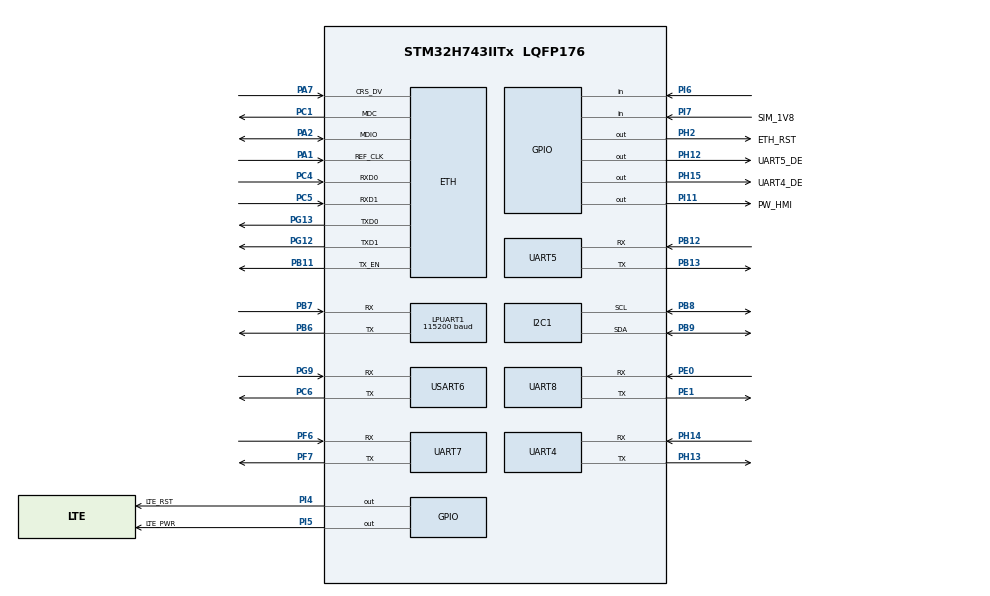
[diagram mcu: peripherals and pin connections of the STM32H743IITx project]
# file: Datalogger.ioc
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CORTEX_M7.AccessPermission_S-Cortex_Memory_Protection_Unit_Region1_Settings_S=MPU_REGION_FULL_ACCESS
CORTEX_M7.AccessPermission_S-Cortex_Memory_Protection_Unit_Region2_Settings_S=MPU_REGION_FULL_ACCESS
CORTEX_M7.AccessPermission_Spec=MPU_REGION_NO_ACCESS
CORTEX_M7.BaseAddress_S-Cortex_Memory_Protection_Unit_Region1_Settings_S=0x30020000
CORTEX_M7.BaseAddress_S-Cortex_Memory_Protection_Unit_Region2_Settings_S=30040000
CORTEX_M7.BaseAddress_Spec=0x0
CORTEX_M7.CPU_DCache=Enabled
CORTEX_M7.CPU_ICache=Enabled
CORTEX_M7.DisableExec_S-Cortex_Memory_Protection_Unit_Region1_Settings_S=MPU_INSTRUCTION_ACCESS_DISABLE
CORTEX_M7.DisableExec_S-Cortex_Memory_Protection_Unit_Region2_Settings_S=MPU_INSTRUCTION_ACCESS_DISABLE
CORTEX_M7.DisableExec_Spec=MPU_INSTRUCTION_ACCESS_DISABLE
CORTEX_M7.Enable_S-Cortex_Memory_Protection_Unit_Region1_Settings_S=MPU_REGION_ENABLE
CORTEX_M7.Enable_S-Cortex_Memory_Protection_Unit_Region2_Settings_S=MPU_REGION_ENABLE
CORTEX_M7.Enable_Spec=__NULL
CORTEX_M7.IsBufferable_S-Cortex_Memory_Protection_Unit_Region2_Settings_S=MPU_ACCESS_BUFFERABLE
CORTEX_M7.IsBufferable_Spec=MPU_ACCESS_NOT_BUFFERABLE
CORTEX_M7.IsCacheable_S-Cortex_Memory_Protection_Unit_Region1_Settings_S=MPU_ACCESS_NOT_CACHEABLE
CORTEX_M7.IsCacheable_Spec=MPU_ACCESS_NOT_CACHEABLE
CORTEX_M7.IsShareable_S-Cortex_Memory_Protection_Unit_Region2_Settings_S=MPU_ACCESS_SHAREABLE
CORTEX_M7.IsShareable_Spec=MPU_ACCESS_SHAREABLE
CORTEX_M7.MPU_Control=MPU_PRIVILEGED_DEFAULT
CORTEX_M7.Size_S-Cortex_Memory_Protection_Unit_Region1_Settings_S=MPU_REGION_SIZE_128KB
CORTEX_M7.Size_S-Cortex_Memory_Protection_Unit_Region2_Settings_S=MPU_REGION_SIZE_512B
CORTEX_M7.Size_Spec=MPU_REGION_SIZE_4GB
CORTEX_M7.SubRegionDisable_Spec=0x87
CORTEX_M7.TypeExtField_S-Cortex_Memory_Protection_Unit_Region1_Settings_S=MPU_TEX_LEVEL1
CORTEX_M7.TypeExtField_Spec=MPU_TEX_LEVEL0
CORTEX_M7.default_mode_Activation=1
ETH.MediaInterface=HAL_ETH_RMII_MODE
ETH.RxBufferAddress=0x30040260
ETH.RxDescAddress=0x30040000
ETH.TxDescAddress=0x30040200
FREERTOS.Tasks01=defaultTask,24,256,StartDefaultTask,Default,NULL,Dynamic,NULL,NULL
FREERTOS.configCHECK_FOR_STACK_OVERFLOW=2
FREERTOS.configMINIMAL_STACK_SIZE=256
FREERTOS.configRECORD_STACK_HIGH_ADDRESS=1
FREERTOS.configTOTAL_HEAP_SIZE=40000
FREERTOS.configUSE_NEWLIB_REENTRANT=1
FREERTOS.configUSE_STATS_FORMATTING_FUNCTIONS=1
I2C1.Timing=0x2050517A
LPUART1.BaudRate=115200
LWIP.BSP.number=1
LWIP.GATEWAY_ADDRESS=192.168.001.001
LWIP.IP_ADDRESS=192.168.110.056
LWIP.LWIP_DHCP=1
LWIP.LWIP_DNS=1
LWIP.LWIP_IPV6=0
LWIP.LWIP_RAM_HEAP_POINTER=0x30020000
LWIP.LWIP_SNTP=1
LWIP.LWIP_STATS=1
LWIP.MEM_SIZE=131048
LWIP.NETMASK_ADDRESS=255.255.255.000
LWIP.PPPOE_SUPPORT=1
LWIP.PPPOL2TP_AUTH_SUPPORT=0
LWIP.PPPOL2TP_SUPPORT=0
LWIP.PPP_NOTIFY_PHASE=1
LWIP.PPP_SUPPORT=1
LWIP.Version=v2.1.2_Cube
LWIP0.BSP.STBoard=false
LWIP0.BSP.api=BSP_COMPONENT_DRIVER
LWIP0.BSP.component=LAN8742
LWIP0.BSP.instance=LAN8742
LWIP0.BSP.name=Driver_PHY
LWIP0.BSP.semaphore=S_LAN8742
LWIP0.BSP.solution=LAN8742
Mcu.Family=STM32H7
Mcu.Name=STM32H743IITx
Mcu.Package=LQFP176
NVIC.ETH_IRQn=true\:5\:0\:false\:false\:true\:true\:true\:true\:true
NVIC.I2C1_EV_IRQn=true\:5\:0\:false\:false\:true\:true\:true\:true\:true
NVIC.LPUART1_IRQn=true\:5\:0\:false\:false\:true\:true\:true\:true\:true
NVIC.PriorityGroup=NVIC_PRIORITYGROUP_4
NVIC.TIM1_UP_IRQn=true\:5\:0\:false\:false\:true\:true\:true\:true\:true
NVIC.TIM2_IRQn=true\:5\:0\:false\:false\:true\:true\:true\:true\:true
NVIC.TIM3_IRQn=true\:5\:0\:false\:false\:true\:true\:true\:true\:true
NVIC.TIM4_IRQn=true\:5\:0\:false\:false\:true\:true\:true\:true\:true
NVIC.TIM5_IRQn=true\:5\:0\:false\:false\:true\:true\:true\:true\:true
NVIC.TIM6_DAC_IRQn=true\:15\:0\:false\:false\:true\:false\:false\:true\:true
NVIC.TimeBase=TIM6_DAC_IRQn
NVIC.TimeBaseIP=TIM6
NVIC.UART4_IRQn=true\:5\:0\:false\:false\:true\:true\:true\:true\:true
NVIC.UART5_IRQn=true\:5\:0\:false\:false\:true\:true\:true\:true\:true
NVIC.UART7_IRQn=true\:5\:0\:false\:false\:true\:true\:true\:true\:true
NVIC.UART8_IRQn=true\:5\:0\:false\:false\:true\:true\:true\:true\:true
NVIC.USART6_IRQn=true\:5\:0\:false\:false\:true\:true\:true\:true\:true
PA1.Mode=RMII
PA1.Signal=ETH_REF_CLK
PA13\ (JTMS/SWDIO).Mode=Serial_Wire
PA13\ (JTMS/SWDIO).Signal=DEBUG_JTMS-SWDIO
PA14\ (JTCK/SWCLK).Mode=Serial_Wire
PA14\ (JTCK/SWCLK).Signal=DEBUG_JTCK-SWCLK
PA2.Mode=RMII
PA2.Signal=ETH_MDIO
PA7.Mode=RMII
PA7.Signal=ETH_CRS_DV
PB11.Mode=RMII
PB11.Signal=ETH_TX_EN
PB12.Mode=Asynchronous
PB12.Signal=UART5_RX
PB13.Mode=Asynchronous
PB13.Signal=UART5_TX
PB6.Mode=Asynchronous
PB6.Signal=LPUART1_TX
PB7.Mode=Asynchronous
PB7.Signal=LPUART1_RX
PB8.Mode=I2C
PB8.Signal=I2C1_SCL
PB9.Mode=I2C
PB9.Signal=I2C1_SDA
PC1.Mode=RMII
PC1.Signal=ETH_MDC
PC4.Mode=RMII
PC4.Signal=ETH_RXD0
PC5.Mode=RMII
PC5.Signal=ETH_RXD1
PC6.Mode=Asynchronous
PC6.Signal=USART6_TX
PE0.Mode=Asynchronous
PE0.Signal=UART8_RX
PE1.Mode=Asynchronous
PE1.Signal=UART8_TX
PF6.Mode=Asynchronous
PF6.Signal=UART7_RX
PF7.Mode=Asynchronous
PF7.Signal=UART7_TX
PG12.Mode=RMII
PG12.Signal=ETH_TXD1
PG13.Mode=RMII
PG13.Signal=ETH_TXD0
PG9.Mode=Asynchronous
PG9.Signal=USART6_RX
PH0-OSC_IN\ (PH0).Mode=HSE-External-Oscillator
PH0-OSC_IN\ (PH0).Signal=RCC_OSC_IN
PH1-OSC_OUT\ (PH1).Mode=HSE-External-Oscillator
PH1-OSC_OUT\ (PH1).Signal=RCC_OSC_OUT
PH12.GPIO_Label=UART5_DE
PH12.Signal=GPIO_Output
PH13.Mode=Asynchronous
PH13.Signal=UART4_TX
PH14.Mode=Asynchronous
PH14.Signal=UART4_RX
PH15.GPIO_Label=UART4_DE
PH15.Signal=GPIO_Output
PH2.GPIO_Label=ETH_RST
PH2.Signal=GPIO_Output
PI11.GPIO_Label=PW_HMI
PI11.Signal=GPIO_Output
PI4.GPIO_Label=LTE_RST
PI4.Signal=GPIO_Output
PI5.GPIO_Label=LTE_PWR
PI5.Signal=GPIO_Output
PI6.Signal=GPIO_Input
PI7.GPIO_Label=SIM_1V8
PI7.Signal=GPIO_Input
ProjectManager.HeapSize=0x2000
ProjectManager.StackSize=0x4000
ProjectManager.TargetToolchain=STM32CubeIDE
RCC.ADCFreq_Value=16125000
RCC.APB1Freq_Value=62500000
RCC.APB2Freq_Value=62500000
RCC.APB3Freq_Value=62500000
RCC.APB4Freq_Value=62500000
RCC.CortexFreq_Value=250000000
RCC.D1PPRE=RCC_APB3_DIV2
RCC.D2PPRE1=RCC_APB1_DIV2
RCC.D2PPRE2=RCC_APB2_DIV2
RCC.D3PPRE=RCC_APB4_DIV2
RCC.DIVM1=1
RCC.DIVN1=62
RCC.HCLKFreq_Value=125000000
RCC.HPRE=RCC_HCLK_DIV2
RCC.HSE_VALUE=8000000
RCC.PLL2FRACN=0
RCC.PLL3FRACN=0
RCC.PLLFRACN=4096
RCC.PLLSourceVirtual=RCC_PLLSOURCE_HSE
RCC.SYSCLKFreq_VALUE=250000000
RCC.SYSCLKSource=RCC_SYSCLKSOURCE_PLLCLK
RCC.USBFreq_Value=250000000
TIM1.Period=999
TIM1.Prescaler=124
TIM2.Period=9999
TIM2.Prescaler=124
USART6.SwapParam=ADVFEATURE_SWAP_DISABLE
USART6.VirtualMode-Asynchronous=VM_ASYNC
VP_FREERTOS_VS_CMSIS_V2.Mode=CMSIS_V2
VP_LWIP_VS_Enabled.Mode=Enabled
VP_MEMORYMAP_VS_MEMORYMAP.Mode=CurAppReg
VP_SYS_VS_tim6.Mode=TIM6
VP_TIM1_VS_ClockSourceINT.Mode=Internal
VP_TIM2_VS_ClockSourceINT.Mode=Internal
VP_TIM3_VS_ClockSourceINT.Mode=Internal
VP_TIM4_VS_ClockSourceINT.Mode=Internal
VP_TIM5_VS_ClockSourceINT.Mode=Internal
board=custom

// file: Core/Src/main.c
/* USER CODE BEGIN Header */
/**
  ******************************************************************************
  * @file           : main.c
  * @brief          : Main program body
  ******************************************************************************
  * @attention
  *
  * Copyright (c) 2025 STMicroelectronics.
  * All rights reserved.
  *
  * This software is licensed under terms that can be found in the LICENSE file
  * in the root directory of this software component.
  * If no LICENSE file comes with this software, it is provided AS-IS.
  *
  ******************************************************************************
  */
/* USER CODE END Header */
#include "main.h"
#include "cmsis_os.h"
#include "i2c.h"
#include "usart.h"
#include "lwip.h"
#include "tim.h"
#include "gpio.h"

/* USER CODE BEGIN Includes */
#include "board.h"
/* USER CODE END Includes */

void SystemClock_Config(void);
static void MPU_Config(void);
void MX_FREERTOS_Init(void);

int main(void)
{

  /* USER CODE BEGIN 1 */
  int wait = 10000000;
  while (wait-- >0);
  /* USER CODE END 1 */

  /* MPU Configuration--------------------------------------------------------*/
  MPU_Config();

  /* Enable the CPU Cache */

  /* Enable I-Cache---------------------------------------------------------*/
  SCB_EnableICache();

  /* Enable D-Cache---------------------------------------------------------*/
  SCB_EnableDCache();

  /* MCU Configuration--------------------------------------------------------*/

  /* Reset of all peripherals, Initializes the Flash interface and the Systick. */
  HAL_Init();

  /* Configure the system clock */
  SystemClock_Config();

  /* Initialize all configured peripherals */
  MX_GPIO_Init();
  bsp_power_off_hmi();
  MX_I2C1_Init();
  MX_LPUART1_UART_Init();
  MX_UART4_Init();
  MX_UART5_Init();
  MX_UART7_Init();
  MX_UART8_Init();
  MX_TIM1_Init();
  MX_TIM2_Init();
  MX_TIM3_Init();
  MX_TIM4_Init();
  MX_TIM5_Init();
  MX_USART6_UART_Init();
  /* USER CODE BEGIN 2 */
  HAL_Delay(1000);
  /* USER CODE END 2 */

  /* Init scheduler */
  osKernelInitialize();  /* Call init function for freertos objects (in cmsis_os2.c) */
  MX_FREERTOS_Init();

  /* Start scheduler */
  osKernelStart();

  /* We should never get here as control is now taken by the scheduler */

  /* Infinite loop */
  while (1)
  {

  }
}

void SystemClock_Config(void)
{
  RCC_OscInitTypeDef RCC_OscInitStruct = {0};
  RCC_ClkInitTypeDef RCC_ClkInitStruct = {0};

  /** Supply configuration update enable
  */
  HAL_PWREx_ConfigSupply(PWR_LDO_SUPPLY);

  /** Configure the main internal regulator output voltage
  */
  __HAL_PWR_VOLTAGESCALING_CONFIG(PWR_REGULATOR_VOLTAGE_SCALE2);

  while(!__HAL_PWR_GET_FLAG(PWR_FLAG_VOSRDY)) {}

  /** Initializes the RCC Oscillators according to the specified parameters
  * in the RCC_OscInitTypeDef structure.
  */
  RCC_OscInitStruct.OscillatorType = RCC_OSCILLATORTYPE_HSE;
  RCC_OscInitStruct.HSEState = RCC_HSE_ON;
  RCC_OscInitStruct.PLL.PLLState = RCC_PLL_ON;
  RCC_OscInitStruct.PLL.PLLSource = RCC_PLLSOURCE_HSE;
  RCC_OscInitStruct.PLL.PLLM = 1;
  RCC_OscInitStruct.PLL.PLLN = 62;
  RCC_OscInitStruct.PLL.PLLP = 2;
  RCC_OscInitStruct.PLL.PLLQ = 2;
  RCC_OscInitStruct.PLL.PLLR = 2;
  RCC_OscInitStruct.PLL.PLLRGE = RCC_PLL1VCIRANGE_3;
  RCC_OscInitStruct.PLL.PLLVCOSEL = RCC_PLL1VCOWIDE;
  RCC_OscInitStruct.PLL.PLLFRACN = 4096;
  if (HAL_RCC_OscConfig(&RCC_OscInitStruct) != HAL_OK)
  {
    Error_Handler();
  }

  /** Initializes the CPU, AHB and APB buses clocks
  */
  RCC_ClkInitStruct.ClockType = RCC_CLOCKTYPE_HCLK|RCC_CLOCKTYPE_SYSCLK
                              |RCC_CLOCKTYPE_PCLK1|RCC_CLOCKTYPE_PCLK2
                              |RCC_CLOCKTYPE_D3PCLK1|RCC_CLOCKTYPE_D1PCLK1;
  RCC_ClkInitStruct.SYSCLKSource = RCC_SYSCLKSOURCE_PLLCLK;
  RCC_ClkInitStruct.SYSCLKDivider = RCC_SYSCLK_DIV1;
  RCC_ClkInitStruct.AHBCLKDivider = RCC_HCLK_DIV2;
  RCC_ClkInitStruct.APB3CLKDivider = RCC_APB3_DIV2;
  RCC_ClkInitStruct.APB1CLKDivider = RCC_APB1_DIV2;
  RCC_ClkInitStruct.APB2CLKDivider = RCC_APB2_DIV2;
  RCC_ClkInitStruct.APB4CLKDivider = RCC_APB4_DIV2;

  if (HAL_RCC_ClockConfig(&RCC_ClkInitStruct, FLASH_LATENCY_2) != HAL_OK)
  {
    Error_Handler();
  }
}

 /* MPU Configuration */

void MPU_Config(void)
{
  MPU_Region_InitTypeDef MPU_InitStruct = {0};

  /* Disables the MPU */
  HAL_MPU_Disable();

  /** Initializes and configures the Region and the memory to be protected
  */
  MPU_InitStruct.Enable = MPU_REGION_ENABLE;
  MPU_InitStruct.BaseAddress = 0x30020000;
  MPU_InitStruct.Size = MPU_REGION_SIZE_128KB;
  MPU_InitStruct.SubRegionDisable = 0x0;
  MPU_InitStruct.TypeExtField = MPU_TEX_LEVEL1;
  MPU_InitStruct.AccessPermission = MPU_REGION_FULL_ACCESS;
  MPU_InitStruct.DisableExec = MPU_INSTRUCTION_ACCESS_DISABLE;
  MPU_InitStruct.IsShareable = MPU_ACCESS_NOT_SHAREABLE;
  MPU_InitStruct.IsCacheable = MPU_ACCESS_NOT_CACHEABLE;
  MPU_InitStruct.IsBufferable = MPU_ACCESS_NOT_BUFFERABLE;

  HAL_MPU_ConfigRegion(&MPU_InitStruct);

  /** Initializes and configures the Region and the memory to be protected
  */
  MPU_InitStruct.BaseAddress = 30040000;
  MPU_InitStruct.Size = MPU_REGION_SIZE_512B;
  MPU_InitStruct.TypeExtField = MPU_TEX_LEVEL0;
  MPU_InitStruct.IsShareable = MPU_ACCESS_SHAREABLE;
  MPU_InitStruct.IsBufferable = MPU_ACCESS_BUFFERABLE;

  HAL_MPU_ConfigRegion(&MPU_InitStruct);
  /* Enables the MPU */
  HAL_MPU_Enable(MPU_PRIVILEGED_DEFAULT);

}

void HAL_TIM_PeriodElapsedCallback(TIM_HandleTypeDef *htim)
{
  if (htim->Instance == TIM6)
  {
    HAL_IncTick();
  }
  /* USER CODE BEGIN Callback 1 */
  BSP_TIM_PeriodElapsedCallback(htim);
  /* USER CODE END Callback 1 */
}

void Error_Handler(void)
{
  __disable_irq();
  while (1)
  {
  }
}

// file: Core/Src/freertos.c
/* USER CODE BEGIN Header */
/**
  ******************************************************************************
  * File Name          : freertos.c
  * Description        : Code for freertos applications
  ******************************************************************************
  * @attention
  *
  * Copyright (c) 2025 STMicroelectronics.
  * All rights reserved.
  *
  * This software is licensed under terms that can be found in the LICENSE file
  * in the root directory of this software component.
  * If no LICENSE file comes with this software, it is provided AS-IS.
  *
  ******************************************************************************
  */
/* USER CODE END Header */

#include "FreeRTOS.h"
#include "task.h"
#include "main.h"
#include "cmsis_os.h"

/* USER CODE BEGIN Includes */
#include "app.h"
/* USER CODE END Includes */

/* Definitions for defaultTask */
osThreadId_t defaultTaskHandle;
const osThreadAttr_t defaultTask_attributes = {
  .name = "defaultTask",
  .stack_size = 256 * 4,
  .priority = (osPriority_t) osPriorityNormal,
};

void StartDefaultTask(void *argument);

extern void MX_LWIP_Init(void);
void MX_FREERTOS_Init(void); /* (MISRA C 2004 rule 8.1) */

/* Hook prototypes */
void vApplicationStackOverflowHook(xTaskHandle xTask, signed char *pcTaskName);

/* USER CODE BEGIN 4 */
void vApplicationStackOverflowHook(xTaskHandle xTask, signed char *pcTaskName)
{
   /* Run time stack overflow checking is performed if
   configCHECK_FOR_STACK_OVERFLOW is defined to 1 or 2. This hook function is
   called if a stack overflow is detected. */
}
/* USER CODE END 4 */

void MX_FREERTOS_Init(void) {

  /* Create the thread(s) */
  /* creation of defaultTask */
  defaultTaskHandle = osThreadNew(StartDefaultTask, NULL, &defaultTask_attributes);

}

void StartDefaultTask(void *argument)
{
  /* init code for LWIP */
  MX_LWIP_Init();
  /* USER CODE BEGIN StartDefaultTask */
  app_init();
  /* Infinite loop */
  for(;;)
  {
    app_poll();
    osDelay(1);
  }
  /* USER CODE END StartDefaultTask */
}
